# STM32G414xx register map
File version: 1.0
Registers are 32-bit, read-write, reset 0x0 unless marked. A register's access mark holds for its fields unless they carry their own. Offsets are from the block's base; [hi:lo] are bit positions; {n}, {i} and the like mark numbered series; 'fields as' and 'values as' point back to an identical list.

## HRTIM1
Base 0x40016800
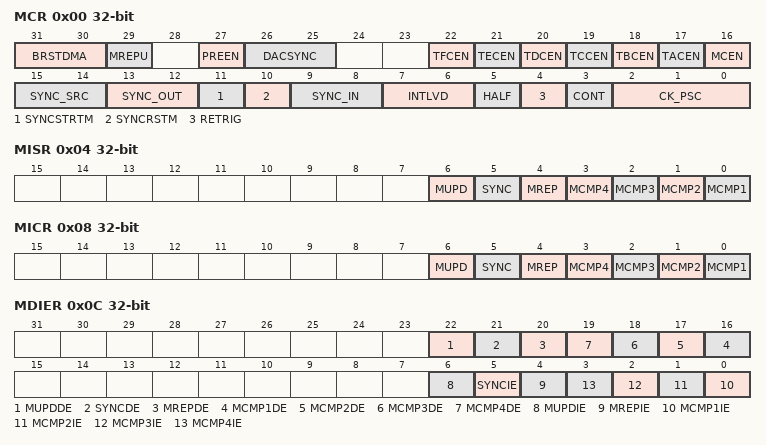
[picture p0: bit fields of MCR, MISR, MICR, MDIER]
0x00 MCR — HRTIM Master Timer control register
  [31:30] BRSTDMA — Burst DMA update
  [29] MREPU — Master repetition update
  [27] PREEN — Master preload enable
  [26:25] DACSYNC — DAC synchronization mask
  [22] TFCEN — Timer F counter enable
  [21] TECEN — Timer E counter enable
  [20] TDCEN — Timer D counter enable
  [19] TCCEN — Timer C counter enable
  [18] TBCEN — Timer B counter enable
  [17] TACEN — Timer A counter enable
  [16] MCEN — Master counter enable
  [15:14] SYNC_SRC — Synchronization source
  [13:12] SYNC_OUT — Synchronization output master
  [11] SYNCSTRTM — Synchronization start master
  [10] SYNCRSTM — Synchronization reset master
  [9:8] SYNC_IN — Synchronization input master
  [7:6] INTLVD — Interleaved mode
  [5] HALF — Half mode
  [4] RETRIG — Rettrigreable mode
  [3] CONT — Continuous mode
  [2:0] CK_PSC — Prescaler mask
0x04 MISR — HRTIM Master Timer interrupt status register
  [6] MUPD — Master update interrupt flag
  [5] SYNC — Synchronization input interrupt flag
  [4] MREP — Master Repetition interrupt flag
  [n-1] MCMP{n} (n=1..4) — Master compare {n} interrupt flag
0x08 MICR — HRTIM Master Timer interrupt clear register
  [6] MUPD — Master update interrupt flag clear
  [5] SYNC — Synchronization input interrupt flag clear
  [4] MREP — Master Repetition interrupt flag clear
  [n-1] MCMP{n} (n=1..4) — Master compare {n} interrupt flag clear
0x0C MDIER — HRTIM Master Timer DMA/interrupt enable register
  [22] MUPDDE — Master update DMA enable
  [21] SYNCDE — Synchronization input DMA enable
  [20] MREPDE — Master Repetition DMA enable
  [n+15] MCMP{n}DE (n=1..4) — Master compare {n} DMA enable
  [6] MUPDIE — Master update interrupt enable
  [5] SYNCIE — Synchronization input interrupt enable
  [4] MREPIE — Master Repetition interrupt enable
  [n-1] MCMP{n}IE (n=1..4) — Master compare {n} interrupt enable
0x10 MCNTR — HRTIM Master Timer counter register
  [15:0] MCNTR — Counter Value
0x14 MPER — HRTIM Master Timer period register
  [15:0] MPER — Period Value
0x18 MREP — HRTIM Master Timer repetition register
  [7:0] MREP — Repetition Value
0x1C MCMP1R — HRTIM Master Timer compare 1 register
  [15:0] MCMP1R — Compare Value
{0x1C+4i} MCMP{i}R (i=2..4) — HRTIM Master Timer compare {i} register
  [15:0] MCMP{i}R — Compare Value
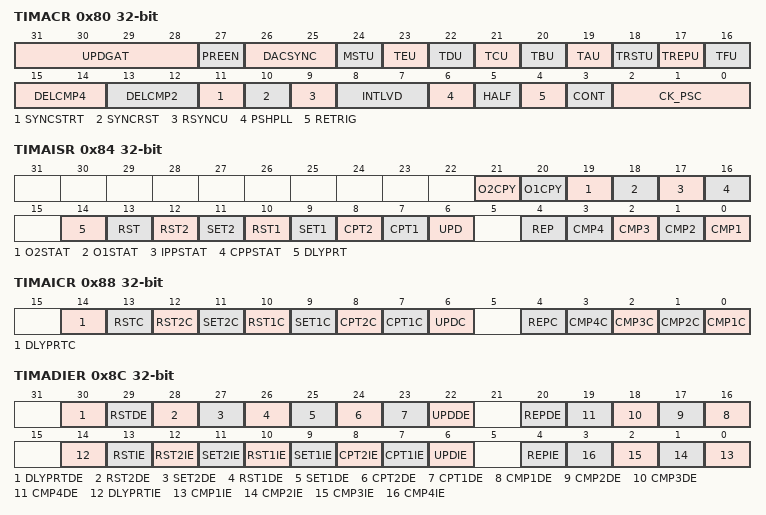
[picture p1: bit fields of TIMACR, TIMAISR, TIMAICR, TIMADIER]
0x80 TIMACR — HRTIM Timerx control register
  [31:28] UPDGAT — Slave update gating mask
  [27] PREEN — Slave preload enable
  [26:25] DACSYNC — DAC synchronization mask
  [24] MSTU — Master Update
  [23] TEU — Slave Timer E update reserved for TIM E
  [22] TDU — Slave Timer D update reserved for TIM D
  [21] TCU — Slave Timer C update reserved for TIM C
  [20] TBU — Slave Timer B update reserved for TIM B
  [19] TAU — Slave Timer A update reserved for TIM A
  [18] TRSTU — Slave reset update
  [17] TREPU — Slave repetition update
  [16] TFU — Slave Timer F update reserved for TIM F
  [15:14] DELCMP4 — Slave delayed compartor 4 mode mask
  [13:12] DELCMP2 — Slave delayed compartor 2 mode mask
  [11] SYNCSTRT — Slave synchronization starts
  [10] SYNCRST — Slave synchronization resets
  [9] RSYNCU — Resynchronization update
  [8:7] INTLVD — Interleaved mode
  [6] PSHPLL — Slave push-pull mode
  [5] HALF — Slave Half mode
  [4] RETRIG — Slave Retrigreable mode
  [3] CONT — Slave continuous mode
  [2:0] CK_PSC — Slave prescaler mask
0x84 TIMAISR — HRTIM Timerx interrupt status register
  [21] O2CPY — Slave output 2 copy flag
  [20] O1CPY — Slave output 1 copy flag
  [19] O2STAT — Slave output 2 state flag
  [18] O1STAT — Slave output 1 state flag
  [17] IPPSTAT — Slave idle push-pull flag
  [16] CPPSTAT — Slave current push-pull flag
  [14] DLYPRT — Slave output 1 delay protection interrupt flag
  [13] RST — Slave reset interrupt flag
  [12] RST2 — Slave output 2 reset interrupt flag
  [11] SET2 — Slave output 2 set interrupt flag
  [10] RST1 — Slave output 1 reset interrupt flag
  [9] SET1 — Slave output 1 set interrupt flag
  [8] CPT2 — Slave capture 2 interrupt flag
  [7] CPT1 — Slave capture 1 interrupt flag
  [6] UPD — Slave update interrupt flag
  [4] REP — Slave repetition interrupt flag
  [n-1] CMP{n} (n=1..4) — Slave compare {n} interrupt flag
0x88 TIMAICR — HRTIM Timerx interrupt clear register
  [14] DLYPRTC — Slave output delay protection clear flag
  [13] RSTC — Slave reset clear flag
  [12] RST2C — Slave output 2 reset clear flag
  [11] SET2C — Slave output 2 set clear flag
  [10] RST1C — Slave output 1 reset clear flag
  [9] SET1C — Slave output 1 set clear flag
  [8] CPT2C — Slave capture 2 clear flag
  [7] CPT1C — Slave capture 1 clear flag
  [6] UPDC — Slave update clear flag
  [4] REPC — Slave repetition clear flag
  [n-1] CMP{n}C (n=1..4) — Slave compare {n} clear flag
0x8C TIMADIER — HRTIM Timerx DMA/interrupt enable register
  [30] DLYPRTDE — Slavedelay protection request enable
  [29] RSTDE — Slave reset request enable
  [28] RST2DE — Slave output 2 reset request enable
  [27] SET2DE — Slave output 2 set request enable
  [26] RST1DE — Slave output 1 reset request enable
  [25] SET1DE — Slave output 1 set request enable
  [24] CPT2DE — Slave capture 2 request enable
  [23] CPT1DE — Slave capture 1 request enable
  [22] UPDDE — Slave update request enable
  [20] REPDE — Slave repetition request enable
  [n+15] CMP{n}DE (n=1..4) — Slave compare {n} request enable
  [14] DLYPRTIE — Slave delay protection interrupt enable
  [13] RSTIE — Slave reset interrupt enable
  [12] RST2IE — Slave output 2 reset interrupt enable
  [11] SET2IE — Slave output 2 set interrupt enable
  [10] RST1IE — Slave output 1 reset interrupt enable
  [9] SET1IE — Slave output 1 set interrupt enable
  [8] CPT2IE — Slave capture 2 interrupt enable
  [7] CPT1IE — Slave capture 1 interrupt enable
  [6] UPDIE — Slave update interrupt enable
  [4] REPIE — Slave repetition interrupt enable
  [n-1] CMP{n}IE (n=1..4) — Slave compare {n} interrupt enable
0x90 CNTAR — HRTIM Timerx counter register
  [15:0] CNTR — Counter Value
0x94 PERAR — HRTIM Timerx period register
0x98 REPAR — HRTIM Timerx repetition register
0x9C CMP1AR — HRTIM Timerx compare 1 register
  [15:0] CMP1R — Compare Value
0xA0 CMP1CAR — HRTIM Timerx compare 1 compound register
  [15:0] CMP1CR — Compare Value
{0x9C+4i} CMP{i}AR (i=2..4) — HRTIM Timerx compare {i} register
  [15:0] CMP{i}R — Compare Value
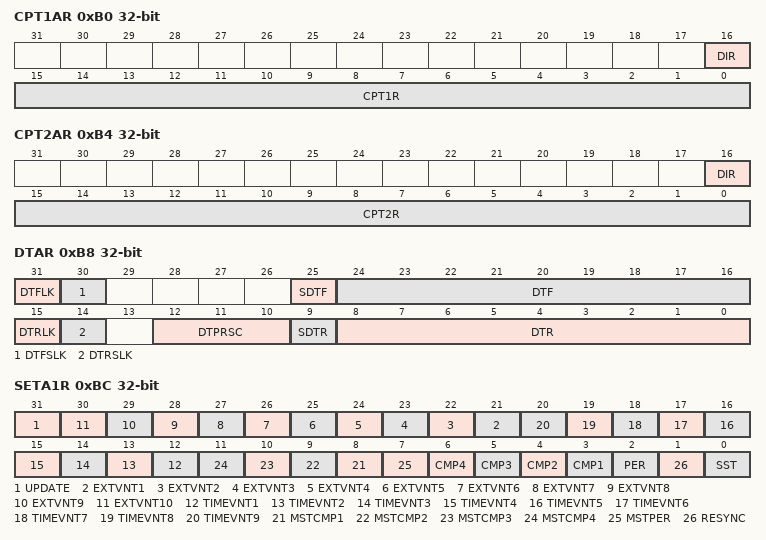
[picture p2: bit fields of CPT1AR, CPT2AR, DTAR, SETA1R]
0xB0 CPT1AR — HRTIM Timerx capture 1 register
  [16] DIR — Capture 1 direction>
  [15:0] CPT1R — Capture 1 Value
0xB4 CPT2AR — HRTIM Timerx capture 2 register
  [16] DIR — Capture 2 direction
  [15:0] CPT2R — Capture 2 Value
0xB8 DTAR — HRTIM Timerx dead time register
  [31] DTFLK — Dead time falling lock
  [30] DTFSLK — Dead time falling sign lock
  [25] SDTF — Sign dead time falling value
  [24:16] DTF — Dead time falling value
  [15] DTRLK — Dead time rising lock
  [14] DTRSLK — Dead time rising sign lock
  [12:10] DTPRSC — Dead time prescaler
  [9] SDTR — Sign dead time rising value
  [8:0] DTR — Dead time rising value
0xBC SETA1R — HRTIM Timerx output 1 set register
  [31] UPDATE — Register update (transfer preload to active)
  [n+20] EXTVNT{n} (n=1..10) — External event {n}
  [n+11] TIMEVNT{n} (n=1..9) — Timer event {n}
  [n+7] MSTCMP{n} (n=1..4) — Master compare {n}
  [7] MSTPER — Master period
  [n+2] CMP{n} (n=1..4) — Timer A compare {n}
  [2] PER — Timer A period
  [1] RESYNC — Timer A resynchronization
  [0] SST — software set trigger
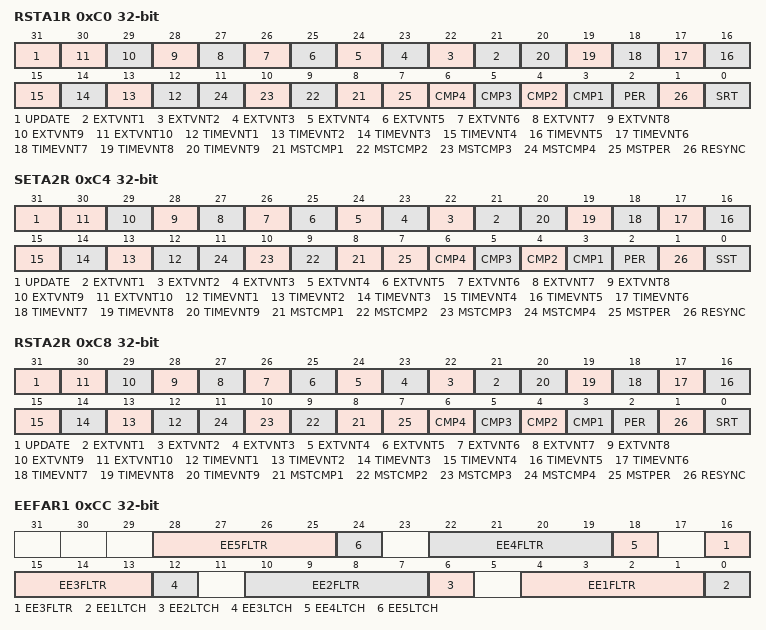
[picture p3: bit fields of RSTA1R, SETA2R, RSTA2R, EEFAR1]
0xC0 RSTA1R — HRTIM Timerx output 1 reset register
  [31] UPDATE — Register update (transfer preload to active)
  [n+20] EXTVNT{n} (n=1..10) — External event {n}
  [n+11] TIMEVNT{n} (n=1..9) — Timer event {n}
  [n+7] MSTCMP{n} (n=1..4) — Master compare {n}
  [7] MSTPER — Master period
  [n+2] CMP{n} (n=1..4) — Timer A compare {n}
  [2] PER — Timer A period
  [1] RESYNC — Timer A resynchronization
  [0] SRT — software reset trigger
0xC4 SETA2R — HRTIM Timerx output 2 set register
  fields as SETA1R
0xC8 RSTA2R — HRTIM Timerx output 2 reset register
  fields as RSTA1R
0xCC EEFAR1 — HRTIM Timerx external event filtering 1 register
  [6n-2:6n-5] EE{n}FLTR (n=1..5) — External Event {n} filter mask
  [6n-6] EE{n}LTCH (n=1..5) — External Event {n} latch
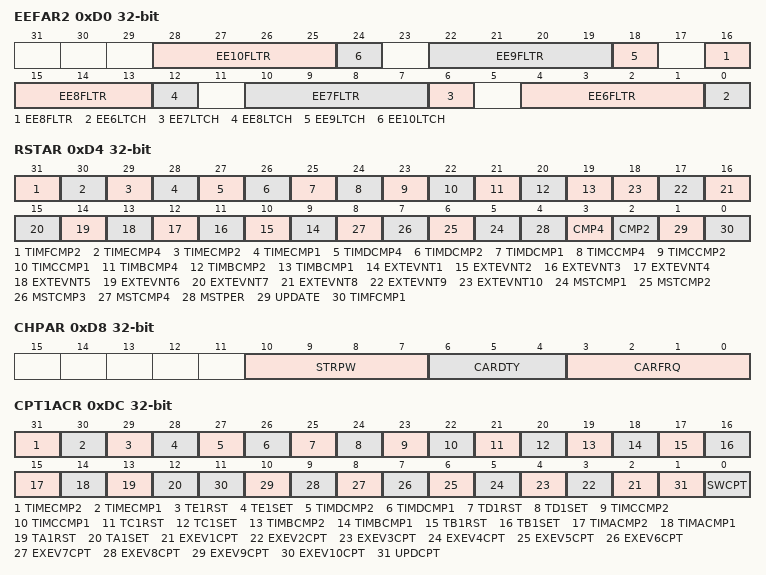
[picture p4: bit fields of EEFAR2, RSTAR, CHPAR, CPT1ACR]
0xD0 EEFAR2 — HRTIM Timerx external event filtering 2 register
  [6n-32:6n-35] EE{n}FLTR (n=6..10) — External Event {n} filter mask
  [6n-36] EE{n}LTCH (n=6..10) — External Event {n} latch
0xD4 RSTAR — HRTIM Timerx Reset register
  [31] TIMFCMP2 — Timer F compare 2
  [30] TIMECMP4 — Timer E compare 4
  [29] TIMECMP2 — Timer E compare 2
  [28] TIMECMP1 — Timer E compare 1
  [27] TIMDCMP4 — Timer D compare 4
  [26] TIMDCMP2 — Timer D compare 2
  [25] TIMDCMP1 — Timer D compare 1
  [24] TIMCCMP4 — Timer C compare 4
  [23] TIMCCMP2 — Timer C compare 2
  [22] TIMCCMP1 — Timer C compare 1
  [21] TIMBCMP4 — Timer B compare 4
  [20] TIMBCMP2 — Timer B compare 2
  [19] TIMBCMP1 — Timer B compare 1
  [n+8] EXTEVNT{n} (n=1..10) — External event {n}
  [n+4] MSTCMP{n} (n=1..4) — Master compare{n}
  [4] MSTPER — Master period
  [3] CMP4 — Timer compare4
  [2] CMP2 — Timer compare2
  [1] UPDATE — Timer update
  [0] TIMFCMP1 — Timer F compare 1
0xD8 CHPAR — HRTIM Timerx Chopper register
  [10:7] STRPW — Timer start pulse width value
  [6:4] CARDTY — Timer chopper duty cycle value
  [3:0] CARFRQ — Timer carrier frequency value
0xDC CPT1ACR — HRTIM Timerx Capture 1 register
  [31] TIMECMP2 — Timer E compare 2
  [30] TIMECMP1 — Timer E compare 1
  [29] TE1RST — Timer E output 1 reset
  [28] TE1SET — Timer E output 1 set
  [27] TIMDCMP2 — Timer D compare 2
  [26] TIMDCMP1 — Timer D compare 1
  [25] TD1RST — Timer D output 1 reset
  [24] TD1SET — Timer D output 1 set
  [23] TIMCCMP2 — Timer C compare 2
  [22] TIMCCMP1 — Timer C compare 1
  [21] TC1RST — Timer C output 1 reset
  [20] TC1SET — Timer C output 1 set
  [19] TIMBCMP2 — Timer B compare 2
  [18] TIMBCMP1 — Timer B compare 1
  [17] TB1RST — Timer B output 1 reset
  [16] TB1SET — Timer B output 1 set
  [15] TIMACMP2 — Timer A compare 2
  [14] TIMACMP1 — Timer A compare 1
  [13] TA1RST — Timer A output 1 reset
  [12] TA1SET — Timer A output 1 set
  [n+1] EXEV{n}CPT (n=1..10) — External event {n} capture
  [1] UPDCPT — Update capture
  [0] SWCPT — Software capture
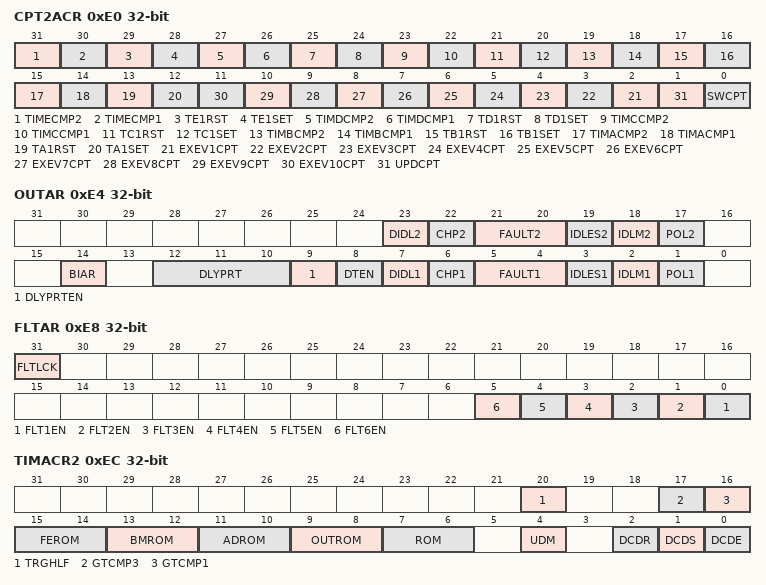
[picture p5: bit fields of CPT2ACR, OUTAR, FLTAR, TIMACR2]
0xE0 CPT2ACR — HRTIM Timerx Capture 2 register
  fields as CPT1ACR
0xE4 OUTAR — HRTIM Timerx Output register
  [23] DIDL2 — Slave output 2 dead time idle
  [22] CHP2 — Slave output 2 chopper enable
  [21:20] FAULT2 — Slave output 2 fault state
  [19] IDLES2 — Slave output 2 idle state
  [18] IDLM2 — Slave output 2 idle mode
  [17] POL2 — Slave output 2 polarity
  [14] BIAR — Slave output Balanced Idle Automatic resume
  [12:10] DLYPRT — Slave output delay protection
  [9] DLYPRTEN — Slave output delay protection enable
  [8] DTEN — Slave output deadtime enable
  [7] DIDL1 — Slave output 1 dead time idle
  [6] CHP1 — Slave output 1 chopper enable
  [5:4] FAULT1 — Slave output 1 fault state
  [3] IDLES1 — Slave output 1 idle state
  [2] IDLM1 — Slave output 1 idle mode
  [1] POL1 — Slave output 1 polarity
0xE8 FLTAR — HRTIM Timerx Fault register
  [31] FLTLCK — Fault sources lock
  [n-1] FLT{n}EN (n=1..6) — Fault {n} enable
0xEC TIMACR2 — HRTIM Timerx Control register 2
  [20] TRGHLF — Triggered-Half mode
  [17] GTCMP3 — Greater than Compare 3 PWM mode
  [16] GTCMP1 — Greater than Compare 1 PWM mode
  [15:14] FEROM — Fault and Event Rollover Mode
  [13:12] BMROM — Burst Mode Rollover Mode
  [11:10] ADROM — ADC Roll-Over Mode
  [9:8] OUTROM — Output Roll-Over Mode
  [7:6] ROM — Roll-over Mode
  [4] UDM — Up-Down Mode
  [2] DCDR — Dual Channel DAC reset trigger
  [1] DCDS — Dual Channel DAC step trigger
  [0] DCDE — Dual Channel DAC trigger enable
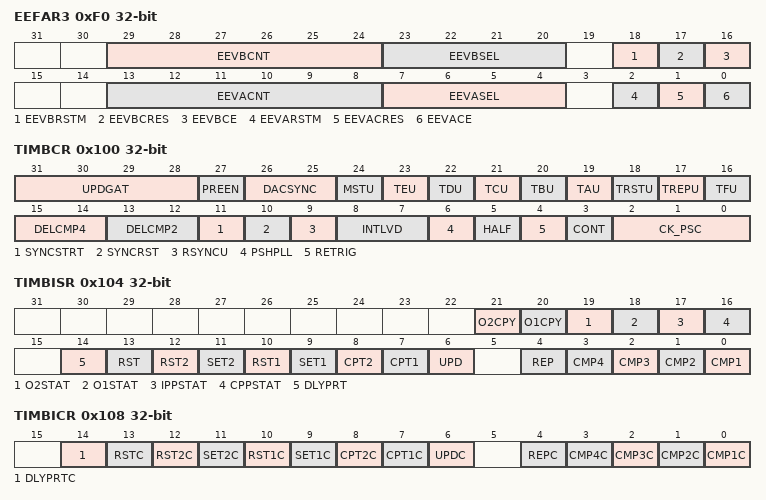
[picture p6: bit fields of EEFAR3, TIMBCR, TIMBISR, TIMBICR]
0xF0 EEFAR3 — HRTIM Timerx external event filtering 3 register
  [29:24] EEVBCNT — External Event B Counter
  [23:20] EEVBSEL — External Event B Selection
  [18] EEVBRSTM — External Event B Counter Reset Mode
  [17] EEVBCRES — External Event B Counter Reset
  [16] EEVBCE — External Event B Counter Enable
  [13:8] EEVACNT — External Event A Selection
  [7:4] EEVASEL — External Event A Selection
  [2] EEVARSTM — External Event A Counter Reset Mode
  [1] EEVACRES — External Event A Counter Reset
  [0] EEVACE — External Event A Counter Enable
0x100 TIMBCR — HRTIM Timerx control register
  fields as TIMACR
0x104 TIMBISR — HRTIM Timerx interrupt status register
  fields as TIMAISR
0x108 TIMBICR — HRTIM Timerx interrupt clear register
  fields as TIMAICR
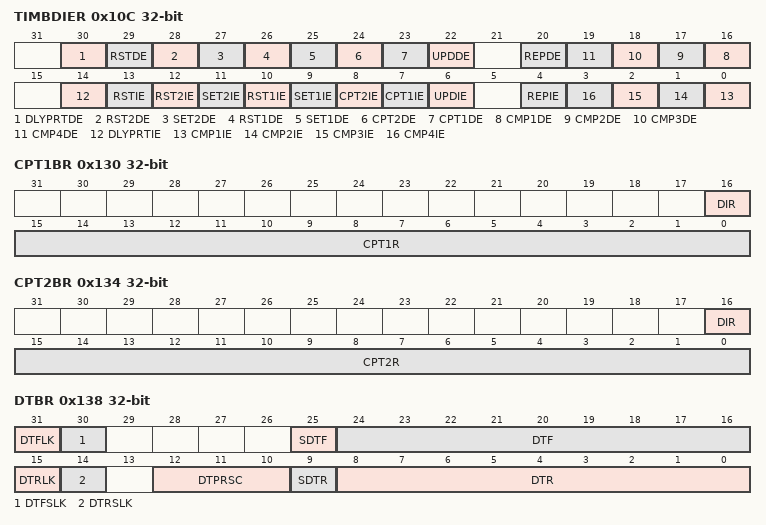
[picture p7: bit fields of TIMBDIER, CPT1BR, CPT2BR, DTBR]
0x10C TIMBDIER — HRTIM Timerx DMA/interrupt enable register
  fields as TIMADIER
0x110 CNTBR — HRTIM Timerx counter register
  [15:0] CNTR — Counter Value
0x114 PERBR — HRTIM Timerx period register
0x118 REPBR — HRTIM Timerx repetition register
0x11C CMP1BR — HRTIM Timerx compare 1 register
  [15:0] CMP1R — Compare Value
0x120 CMP1CBR — HRTIM Timerx compare 1 compound register
  [15:0] CMP1CR — Compare Value
{0x11C+4i} CMP{i}BR (i=2..4) — HRTIM Timerx compare {i} register
  [15:0] CMP{i}R — Compare Value
0x130 CPT1BR — HRTIM Timerx capture 1 register
  [16] DIR — Capture 1 direction>
  [15:0] CPT1R — Capture 1 Value
0x134 CPT2BR — HRTIM Timerx capture 2 register
  [16] DIR — Capture 2 direction
  [15:0] CPT2R — Capture 2 Value
0x138 DTBR — HRTIM Timerx dead time register
  fields as DTAR
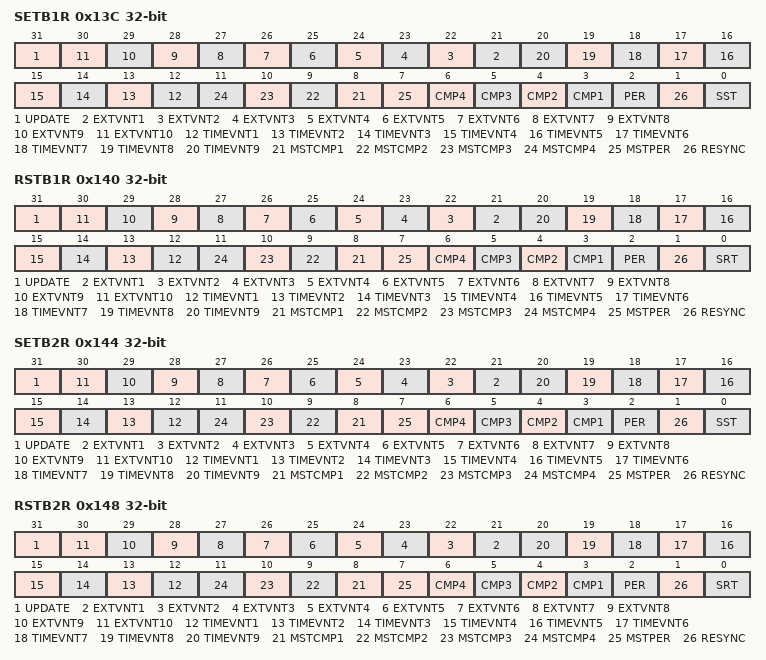
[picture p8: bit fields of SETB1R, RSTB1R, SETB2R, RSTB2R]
0x13C SETB1R — HRTIM Timerx output 1 set register
  fields as SETA1R
0x140 RSTB1R — HRTIM Timerx output 1 reset register
  fields as RSTA1R
0x144 SETB2R — HRTIM Timerx output 2 set register
  fields as SETA1R
0x148 RSTB2R — HRTIM Timerx output 2 reset register
  fields as RSTA1R
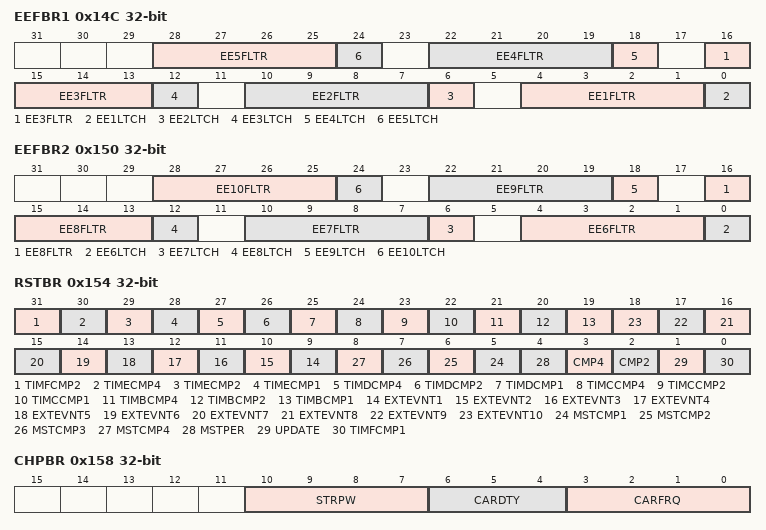
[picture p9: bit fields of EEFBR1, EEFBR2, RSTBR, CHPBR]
0x14C EEFBR1 — HRTIM Timerx external event filtering 1 register
  fields as EEFAR1
0x150 EEFBR2 — HRTIM Timerx external event filtering 2 register
  fields as EEFAR2
0x154 RSTBR — HRTIM Timerx Reset register
  fields as RSTAR
0x158 CHPBR — HRTIM Timerx Chopper register
  fields as CHPAR
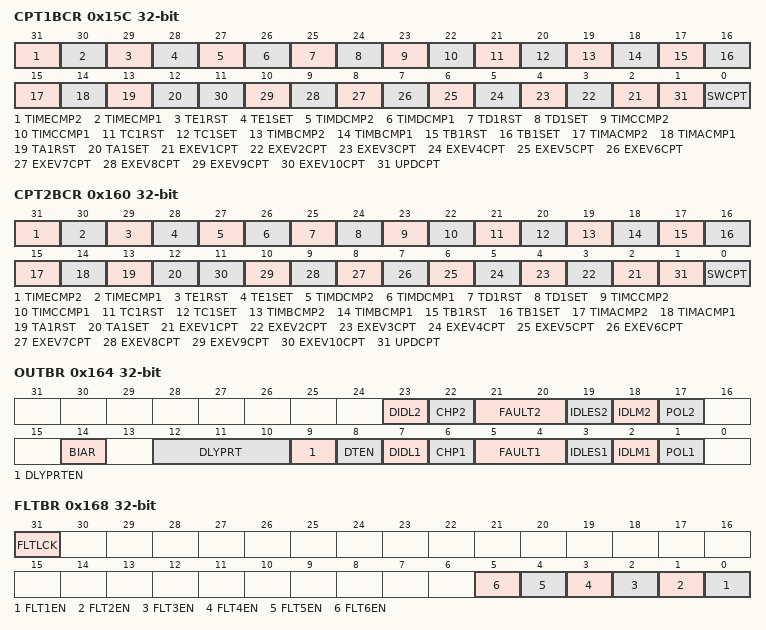
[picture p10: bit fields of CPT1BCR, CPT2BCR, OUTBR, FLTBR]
0x15C CPT1BCR — HRTIM Timerx Capture 1 register
  fields as CPT1ACR
0x160 CPT2BCR — HRTIM Timerx Capture 2 register
  fields as CPT1ACR
0x164 OUTBR — HRTIM Timerx Output register
  fields as OUTAR
0x168 FLTBR — HRTIM Timerx Fault register
  fields as FLTAR
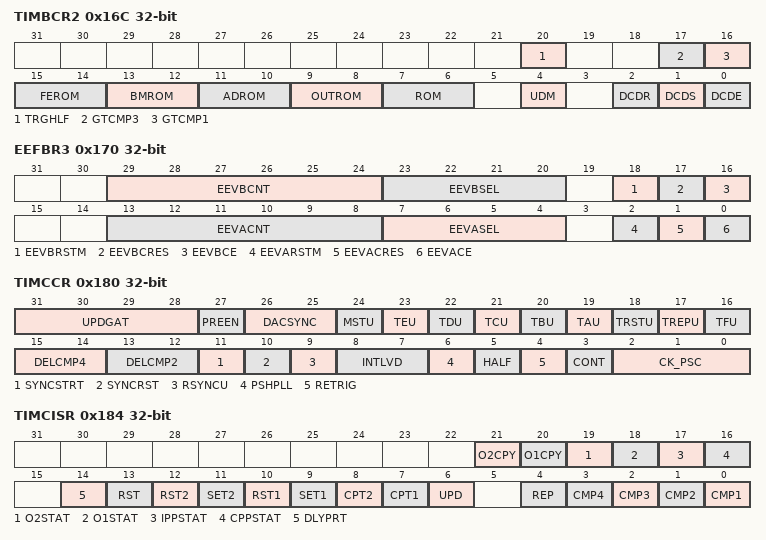
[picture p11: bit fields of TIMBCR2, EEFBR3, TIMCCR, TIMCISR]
0x16C TIMBCR2 — HRTIM Timerx Control register 2
  fields as TIMACR2
0x170 EEFBR3 — HRTIM Timerx external event filtering 3 register
  fields as EEFAR3
0x180 TIMCCR — HRTIM Timerx control register
  fields as TIMACR
0x184 TIMCISR — HRTIM Timerx interrupt status register
  fields as TIMAISR
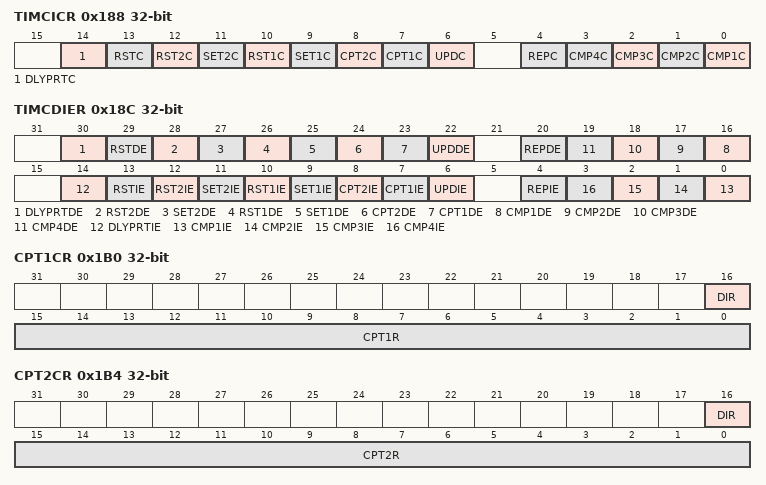
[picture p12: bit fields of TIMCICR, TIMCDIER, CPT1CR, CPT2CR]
0x188 TIMCICR — HRTIM Timerx interrupt clear register
  fields as TIMAICR
0x18C TIMCDIER — HRTIM Timerx DMA/interrupt enable register
  fields as TIMADIER
0x190 CNTCR — HRTIM Timerx counter register
  [15:0] CNTR — Counter Value
0x194 PERCR — HRTIM Timerx period register
0x198 REPCR — HRTIM Timerx repetition register
0x19C CMP1CR — HRTIM Timerx compare 1 register
  [15:0] CMP1R — Compare Value
0x1A0 CMP1CCR — HRTIM Timerx compare 1 compound register
  [15:0] CMP1CR — Compare Value
{0x19C+4i} CMP{i}CR (i=2..4) — HRTIM Timerx compare {i} register
  [15:0] CMP{i}R — Compare Value
0x1B0 CPT1CR — HRTIM Timerx capture 1 register
  [16] DIR — Capture 1 direction>
  [15:0] CPT1R — Capture 1 Value
0x1B4 CPT2CR — HRTIM Timerx capture 2 register
  [16] DIR — Capture 2 direction
  [15:0] CPT2R — Capture 2 Value
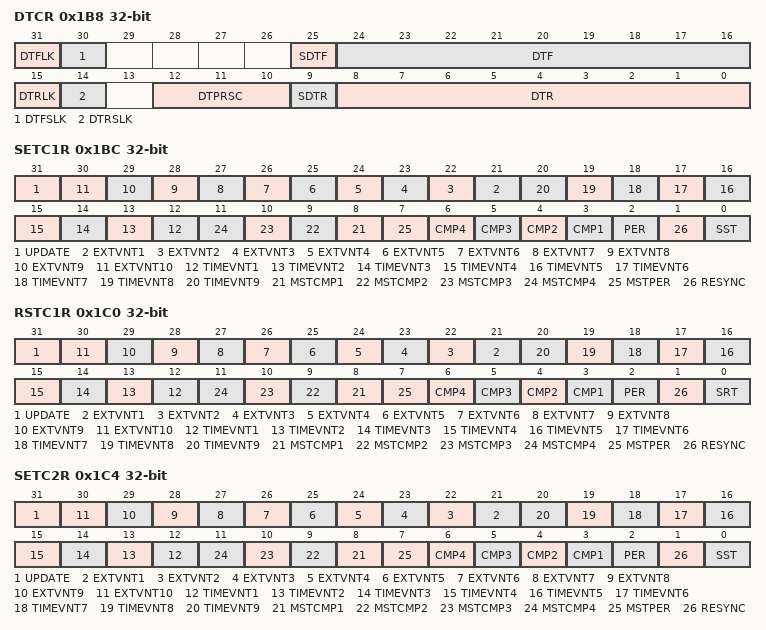
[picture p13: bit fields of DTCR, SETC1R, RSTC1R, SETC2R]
0x1B8 DTCR — HRTIM Timerx dead time register
  fields as DTAR
0x1BC SETC1R — HRTIM Timerx output 1 set register
  fields as SETA1R
0x1C0 RSTC1R — HRTIM Timerx output 1 reset register
  fields as RSTA1R
0x1C4 SETC2R — HRTIM Timerx output 2 set register
  fields as SETA1R
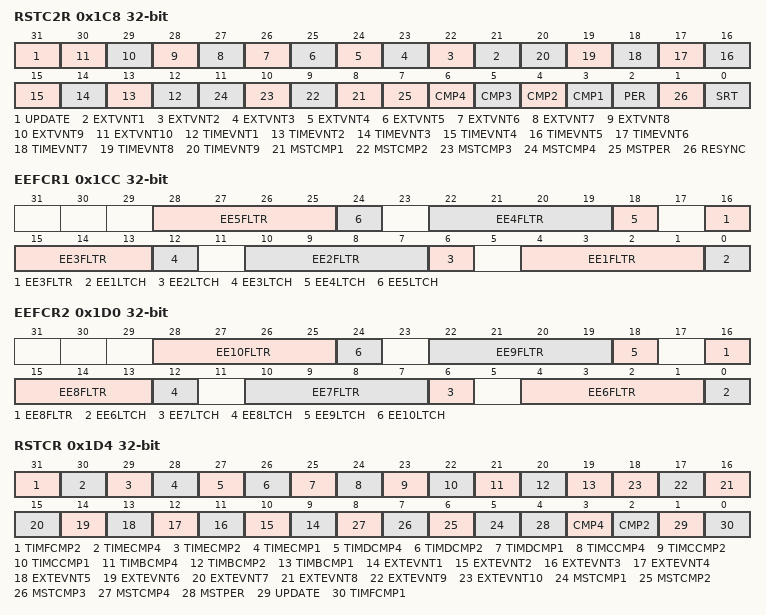
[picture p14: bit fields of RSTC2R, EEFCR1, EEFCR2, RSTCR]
0x1C8 RSTC2R — HRTIM Timerx output 2 reset register
  fields as RSTA1R
0x1CC EEFCR1 — HRTIM Timerx external event filtering 1 register
  fields as EEFAR1
0x1D0 EEFCR2 — HRTIM Timerx external event filtering 2 register
  fields as EEFAR2
0x1D4 RSTCR — HRTIM Timerx Reset register
  fields as RSTAR
0x1D8 CHPCR — HRTIM Timerx Chopper register
  fields as CHPAR
0x1DC CPT1CCR — HRTIM Timerx Capture 1 register
  fields as CPT1ACR
0x1E0 CPT2CCR — HRTIM Timerx Capture 2 register
  fields as CPT1ACR
0x1E4 OUTCR — HRTIM Timerx Output register
  fields as OUTAR
0x1E8 FLTCR — HRTIM Timerx Fault register
  fields as FLTAR
0x1EC TIMCCR2 — HRTIM Timerx Control register 2
  fields as TIMACR2
0x1F0 EEFCR3 — HRTIM Timerx external event filtering 3 register
  fields as EEFAR3
0x200 TIMDCR — HRTIM Timerx control register
  fields as TIMACR
0x204 TIMDISR — HRTIM Timerx interrupt status register
  fields as TIMAISR
0x208 TIMDICR — HRTIM Timerx interrupt clear register
  fields as TIMAICR
0x20C TIMDDIER — HRTIM Timerx DMA/interrupt enable register
  fields as TIMADIER
0x210 CNTDR — HRTIM Timerx counter register
  [15:0] CNTR — Counter Value
0x214 PERDR — HRTIM Timerx period register
0x218 REPDR — HRTIM Timerx repetition register
0x21C CMP1DR — HRTIM Timerx compare 1 register
  [15:0] CMP1R — Compare Value
0x220 CMP1CDR — HRTIM Timerx compare 1 compound register
  [15:0] CMP1CR — Compare Value
{0x21C+4i} CMP{i}DR (i=2..4) — HRTIM Timerx compare {i} register
  [15:0] CMP{i}R — Compare Value
0x230 CPT1DR — HRTIM Timerx capture 1 register
  [16] DIR — Capture 1 direction>
  [15:0] CPT1R — Capture 1 Value
0x234 CPT2DR — HRTIM Timerx capture 2 register
  [16] DIR — Capture 2 direction
  [15:0] CPT2R — Capture 2 Value
0x238 DTDR — HRTIM Timerx dead time register
  fields as DTAR
0x23C SETD1R — HRTIM Timerx output 1 set register
  fields as SETA1R
0x240 RSTD1R — HRTIM Timerx output 1 reset register
  fields as RSTA1R
0x244 SETD2R — HRTIM Timerx output 2 set register
  fields as SETA1R
0x248 RSTD2R — HRTIM Timerx output 2 reset register
  fields as RSTA1R
0x24C EEFDR1 — HRTIM Timerx external event filtering 1 register
  fields as EEFAR1
0x250 EEFDR2 — HRTIM Timerx external event filtering 2 register
  fields as EEFAR2
0x254 RSTDR — HRTIM Timerx Reset register
  fields as RSTAR
0x258 CHPDR — HRTIM Timerx Chopper register
  fields as CHPAR
0x25C CPT1DCR — HRTIM Timerx Capture 1 register
  fields as CPT1ACR
0x260 CPT2DCR — HRTIM Timerx Capture 2 register
  fields as CPT1ACR
0x264 OUTDR — HRTIM Timerx Output register
  fields as OUTAR
0x268 FLTDR — HRTIM Timerx Fault register
  fields as FLTAR
0x26C TIMDCR2 — HRTIM Timerx Control register 2
  fields as TIMACR2
0x270 EEFDR3 — HRTIM Timerx external event filtering 3 register
  fields as EEFAR3
0x280 TIMECR — HRTIM Timerx control register
  fields as TIMACR
0x284 TIMEISR — HRTIM Timerx interrupt status register
  fields as TIMAISR
0x288 TIMEICR — HRTIM Timerx interrupt clear register
  fields as TIMAICR
0x28C TIMEDIER — HRTIM Timerx DMA/interrupt enable register
  fields as TIMADIER
0x290 CNTER — HRTIM Timerx counter register
  [15:0] CNTR — Counter Value
0x294 PERER — HRTIM Timerx period register
0x298 REPER — HRTIM Timerx repetition register
0x29C CMP1ER — HRTIM Timerx compare 1 register
  [15:0] CMP1R — Compare Value
0x2A0 CMP1CER — HRTIM Timerx compare 1 compound register
  [15:0] CMP1CR — Compare Value
{0x29C+4i} CMP{i}ER (i=2..4) — HRTIM Timerx compare {i} register
  [15:0] CMP{i}R — Compare Value
0x2B0 CPT1ER — HRTIM Timerx capture 1 register
  [16] DIR — Capture 1 direction>
  [15:0] CPT1R — Capture 1 Value
0x2B4 CPT2ER — HRTIM Timerx capture 2 register
  [16] DIR — Capture 2 direction
  [15:0] CPT2R — Capture 2 Value
0x2B8 DTER — HRTIM Timerx dead time register
  fields as DTAR
0x2BC SETE1R — HRTIM Timerx output 1 set register
  fields as SETA1R
0x2C0 RSTE1R — HRTIM Timerx output 1 reset register
  fields as RSTA1R
0x2C4 SETE2R — HRTIM Timerx output 2 set register
  fields as SETA1R
0x2C8 RSTE2R — HRTIM Timerx output 2 reset register
  fields as RSTA1R
0x2CC EEFER1 — HRTIM Timerx external event filtering 1 register
  fields as EEFAR1
0x2D0 EEFER2 — HRTIM Timerx external event filtering 2 register
  fields as EEFAR2
0x2D4 RSTER — HRTIM Timerx Reset register
  fields as RSTAR
0x2D8 CHPER — HRTIM Timerx Chopper register
  fields as CHPAR
0x2DC CPT1ECR — HRTIM Timerx Capture 1 register
  fields as CPT1ACR
0x2E0 CPT2ECR — HRTIM Timerx Capture 2 register
  fields as CPT1ACR
0x2E4 OUTER — HRTIM Timerx Output register
  fields as OUTAR
0x2E8 FLTER — HRTIM Timerx Fault register
  fields as FLTAR
0x2EC TIMECR2 — HRTIM Timerx Control register 2
  fields as TIMACR2
0x2F0 EEFER3 — HRTIM Timerx external event filtering 3 register
  fields as EEFAR3
0x300 TIMFCR — HRTIM Timerx control register
  fields as TIMACR
0x304 TIMFISR — HRTIM Timerx interrupt status register
  fields as TIMAISR
0x308 TIMFICR — HRTIM Timerx interrupt clear register
  fields as TIMAICR
0x30C TIMFDIER — HRTIM Timerx DMA/interrupt enable register
  fields as TIMADIER
0x310 CNTFR — HRTIM Timerx counter register
  [15:0] CNTR — Counter Value
0x314 PERFR — HRTIM Timerx period register
0x318 REPFR — HRTIM Timerx repetition register
0x31C CMP1FR — HRTIM Timerx compare 1 register
  [15:0] CMP1R — Compare Value
0x320 CMP1CFR — HRTIM Timerx compare 1 compound register
  [15:0] CMP1CR — Compare Value
{0x31C+4i} CMP{i}FR (i=2..4) — HRTIM Timerx compare {i} register
  [15:0] CMP{i}R — Compare Value
0x330 CPT1FR — HRTIM Timerx capture 1 register
  [16] DIR — Capture 1 direction>
  [15:0] CPT1R — Capture 1 Value
0x334 CPT2FR — HRTIM Timerx capture 2 register
  [16] DIR — Capture 2 direction
  [15:0] CPT2R — Capture 2 Value
0x338 DTFR — HRTIM Timerx dead time register
  fields as DTAR
0x33C SETF1R — HRTIM Timerx output 1 set register
  fields as SETA1R
0x340 RSTF1R — HRTIM Timerx output 1 reset register
  fields as RSTA1R
0x344 SETF2R — HRTIM Timerx output 2 set register
  fields as SETA1R
0x348 RSTF2R — HRTIM Timerx output 2 reset register
  fields as RSTA1R
0x34C EEFFR1 — HRTIM Timerx external event filtering 1 register
  fields as EEFAR1
0x350 EEFFR2 — HRTIM Timerx external event filtering 2 register
  fields as EEFAR2
0x354 RSTFR — HRTIM Timerx Reset register
  fields as RSTAR
0x358 CHPFR — HRTIM Timerx Chopper register
  fields as CHPAR
0x35C CPT1FCR — HRTIM Timerx Capture 1 register
  fields as CPT1ACR
0x360 CPT2FCR — HRTIM Timerx Capture 2 register
  fields as CPT1ACR
0x364 OUTFR — HRTIM Timerx Output register
  fields as OUTAR
0x368 FLTFR — HRTIM Timerx Fault register
  fields as FLTAR
0x36C TIMFCR2 — HRTIM Timerx Control register 2
  fields as TIMACR2
0x370 EEFFR3 — HRTIM Timerx external event filtering 3 register
  fields as EEFAR3
0x380 CR1 — HRTIM control register1
  [3n+15:3n+13] ADC{n}USRC (n=1..4) — ADC Trigger {n} update source
  [6] TFUDIS — Timer F update disable
  [5] TEUDIS — Timer E update disable
  [4] TDUDIS — Timer D update disable
  [3] TCUDIS — Timer C update disable
  [2] TBUDIS — Timer B update disable
  [1] TAUDIS — Timer A update disable
  [0] MUDIS — Master update disable
0x384 CR2 — HRTIM control register2
  [21] SWPF — Timer F swap outputs
  [20] SWPE — Timer E swap outputs
  [19] SWPD — Timer D swap outputs
  [18] SWPC — Timer C swap outputs
  [17] SWPB — Timer B swap outputs
  [16] SWPA — Timer A swap outputs
  [14] TFRST — Timer F count software reset
  [13] TERST — Timer E count software reset
  [12] TDRST — Timer D count software reset
  [11] TCRST — Timer C count software reset
  [10] TBRST — Timer B count software reset
  [9] TARST — Timer A count software reset
  [8] MRST — Master count software reset
  [6] TFSWU — Timer F software update
  [5] TESWU — Timer E software update
  [4] TDSWU — Timer D software update
  [3] TCSWU — Timer C software update
  [2] TBSWU — Timer B software update
  [1] TASWU — Timer A software update
  [0] MSWU — Master software update
0x388 ISR — HRTIM interrupt status register
  [17] BMPER — Burst mode period interrupt flag
  [16] DLLRDY — DLL ready interrupt flag
  [6] FLT6 — Fault 6 interrupt flag
  [5] SYSFLT — System Fault interrupt flag
  [n-1] FLT{n} (n=1..5) — Fault {n} interrupt flag
0x38C ICR — HRTIM interrupt clear register
  [17] BMPERC — Burst mode period interrupt flag clear
  [16] DLLRDYC — DLL ready interrupt flag clear
  [6] FLT6C — Fault 6 interrupt flag clear
  [5] SYSFLTC — System Fault interrupt flag clear
  [n-1] FLT{n}C (n=1..5) — Fault {n} interrupt flag clear
0x390 IER — HRTIM interrupt enable register
  [17] BMPER — Burst mode period interrupt enable
  [16] DLLRDY — DLL ready interrupt enable
  [6] FLT6 — Fault 6 interrupt enable
  [5] SYSFLT — System Fault interrupt enable
  [n-1] FLT{n} (n=1..5) — Fault {n} interrupt enable
0x394 OENR — HRTIM Output enable register
  [11] TF2OEN — Timer F Output 2 enable
  [10] TF1OEN — Timer F Output 1 enable
  [9] TE2OEN — Timer E Output 2 enable
  [8] TE1OEN — Timer E Output 1 enable
  [7] TD2OEN — Timer D Output 2 enable
  [6] TD1OEN — Timer D Output 1 enable
  [5] TC2OEN — Timer C Output 2 enable
  [4] TC1OEN — Timer C Output 1 enable
  [3] TB2OEN — Timer B Output 2 enable
  [2] TB1OEN — Timer B Output 1 enable
  [1] TA2OEN — Timer A Output 2 enable
  [0] TA1OEN — Timer A Output 1 enable
0x398 ODISR — HRTIM Output disable register
  [11] TF2ODIS — Timer F Output 2 disable
  [10] TF1ODIS — Timer F Output 1 disable
  [9] TE2ODIS — Timer E Output 2 disable
  [8] TE1ODIS — Timer E Output 1 disable
  [7] TD2ODIS — Timer D Output 2 disable
  [6] TD1ODIS — Timer D Output 1 disable
  [5] TC2ODIS — Timer C Output 2 disable
  [4] TC1ODIS — Timer C Output 1 disable
  [3] TB2ODIS — Timer B Output 2 disable
  [2] TB1ODIS — Timer B Output 1 disable
  [1] TA2ODIS — Timer A Output 2 disable
  [0] TA1ODIS — Timer A Output 1 disable
0x39C ODSR — HRTIM Output disable status register
  [11] TF2ODS — Timer F Output 2 disable status
  [10] TF1ODS — Timer F Output 1 disable status
  [9] TE2ODS — Timer E Output 2 disable status
  [8] TE1ODS — Timer E Output 1 disable status
  [7] TD2ODS — Timer D Output 2 disable status
  [6] TD1ODS — Timer D Output 1 disable status
  [5] TC2ODS — Timer C Output 2 disable status
  [4] TC1ODS — Timer C Output 1 disable status
  [3] TB2ODS — Timer B Output 2 disable status
  [2] TB1ODS — Timer B Output 1 disable status
  [1] TA2ODS — Timer A Output 2 disable status
  [0] TA1ODS — Timer A Output 1 disable status
0x3A0 BMCR — HRTIM Burst mode control register
  [31] BMSTAT — Burst mode status
  [22] TFBM — Timer F Burst mode
  [21] TEBM — Timer E Burst mode
  [20] TDBM — Timer D Burst mode
  [19] TCBM — Timer C Burst mode
  [18] TBBM — Timer B Burst mode
  [17] TABM — Timer A Burst mode
  [16] MTBM — Master Timer Burst mode
  [10] BMPREN — Burst mode Preload bit
  [9:6] BMPRSC — Burst mode prescaler
  [5:2] BMCLK — Burst mode clock source
  [1] BMOM — Burst mode operating mode
  [0] BME — Burst mode enable
0x3A4 BMTRGR — HRTIM Busrt mode trigger register
  [31] OCHPEV — on-chip Event
  [30] EEV8 — External Event 8
  [29] EEV7 — External Event 7
  [28] TDEEV8 — Timer D period following External Event8
  [27] TAEEV7 — Timer A period following External Event7
  [26] TECMP2 — Timer E compare 2
  [25] TECMP1 — Timer E compare 1
  [24] TEREP — Timer E repetition
  [23] TFCMP1 — Timer F compare 1
  [22] TDCMP2 — Timer D compare 2
  [21] TFREP — Timer F repetition
  [20] TDREP — Timer D repetition
  [19] TDRST — Timer D reset
  [18] TFRST — Timer F reset
  [17] TCCMP1 — Timer C compare 1
  [16] TCREP — Timer C repetition
  [15] TCRST — Timer C reset
  [14] TBCMP2 — Timer B compare 2
  [13] TBCMP1 — Timer B compare 1
  [12] TBREP — Timer B repetition
  [11] TBRST — Timer B reset
  [10] TACMP2 — Timer A compare 2
  [9] TACMP1 — Timer A compare 1
  [8] TAREP — Timer A repetition
  [7] TARST — Timer A reset
  [n+2] MSTCMP{n} (n=1..4) — Master compare {n}
  [2] MSTREP — Master repetition
  [1] MSTRST — Master reset
  [0] SW — Software start
0x3A8 BMCMPR — HRTIM Burst mode compare register
  [15:0] BMCMPR — !<Burst Compare Value
0x3AC BMPER — HRTIM Burst mode period register
  [15:0] BMPER — !<Burst period Value
0x3B0 EECR1 — HRTIM Timer external event control register1
  [6n-1] EE{n}FAST (n=1..5) — External event {n} Fast mode
  [6n-2:6n-3] EE{n}SNS (n=1..5) — External event {n} sensitivity
  [6n-4] EE{n}POL (n=1..5) — External event {n} Polarity
  [6n-5:6n-6] EE{n}SRC (n=1..5) — External event {n} source
0x3B4 EECR2 — HRTIM Timer external event control register2
  [6n-32:6n-33] EE{n}SNS (n=6..10) — External event {n} sensitivity
  [6n-34] EE{n}POL (n=6..10) — External event {n} Polarity
  [6n-35:6n-36] EE{n}SRC (n=6..10) — External event {n} source
0x3B8 EECR3 — HRTIM Timer external event control register3
  [31:30] EEVSD — External event sampling clock division
  [6n-33:6n-36] EE{n}F (n=6..10) — External event {n} filter
0x3BC ADC1R — HRTIM ADC Trigger 1 register
  [31] AD1TEPER — ADC Trigger 1 on Timer E compare period
  [30] AD1TEC4 — ADC Trigger 1 on Timer E compare 4
  [29] AD1TEC3 — ADC Trigger 1 on Timer E compare 3
  [28] AD1TFRST — ADC Trigger 1 on Timer F reset
  [27] AD1TDPER — ADC Trigger 1 on Timer D period
  [26] AD1TDC4 — ADC Trigger 1 on Timer D compare 4
  [25] AD1TDC3 — ADC Trigger 1 on Timer D compare 3
  [24] AD1TFPER — ADC Trigger 1 on Timer F period
  [23] AD1TCPER — ADC Trigger 1 on Timer C period
  [22] AD1TCC4 — ADC Trigger 1 on Timer C compare 4
  [21] AD1TCC3 — ADC Trigger 1 on Timer C compare 3
  [20] AD1TFC4 — ADC Trigger 1 on Timer F compare 4
  [19] AD1TBRST — ADC Trigger 1 on Timer B reset
  [18] AD1TBPER — ADC Trigger 1 on Timer B period
  [17] AD1TBC4 — ADC Trigger 1 on Timer B compare 4
  [16] AD1TBC3 — ADC Trigger 1 on Timer B compare 3
  [15] AD1TFC3 — ADC Trigger 1 on Timer F compare 3
  [14] AD1TARST — ADC Trigger 1 on Timer A reset
  [13] AD1TAPER — ADC Trigger 1 on Timer A period
  [12] AD1TAC4 — ADC Trigger 1 on Timer A compare 4
  [11] AD1TAC3 — ADC Trigger 1 on Timer A compare 3
  [10] AD1TFC2 — ADC Trigger 1 on Timer F compare 2
  [n+4] AD1EEV{n} (n=1..5) — ADC Trigger 1 on external event {n}
  [4] AD1MPER — ADC Trigger 1 on master period
  [n-1] AD1MC{n} (n=1..4) — ADC Trigger 1 on master compare {n}
0x3C0 ADC2R — HRTIM ADC Trigger 2 register
  [31] AD2TERST — ADC Trigger 2 on Timer E reset
  [30] AD2TEC4 — ADC Trigger 2 on Timer E compare 4
  [29] AD2TEC3 — ADC Trigger 2 on Timer E compare 3
  [28] AD2TEC2 — ADC Trigger 2 on Timer E compare 2
  [27] AD2TDRST — ADC Trigger 2 on Timer D reset
  [26] AD2TDPER — ADC Trigger 2 on Timer D period
  [25] AD2TDC4 — ADC Trigger 2 on Timer D compare 4
  [24] AD2TFPER — ADC Trigger 2 on Timer F period
  [23] AD2TDC2 — ADC Trigger 2 on Timer D compare 2
  [22] AD2TCRST — ADC Trigger 2 on Timer C reset
  [21] AD2TCPER — ADC Trigger 2 on Timer C period
  [20] AD2TCC4 — ADC Trigger 2 on Timer C compare 4
  [19] AD2TFC4 — ADC Trigger 2 on Timer F compare 4
  [18] AD2TCC2 — ADC Trigger 2 on Timer C compare 2
  [17] AD2TBPER — ADC Trigger 2 on Timer B period
  [16] AD2TBC4 — ADC Trigger 2 on Timer B compare 4
  [15] AD2TFC3 — ADC Trigger 2 on Timer F compare 3
  [14] AD2TBC2 — ADC Trigger 2 on Timer B compare 2
  [13] AD2TAPER — ADC Trigger 2 on Timer A period
  [12] AD2TAC4 — ADC Trigger 2 on Timer A compare 4
  [11] AD2TFC2 — ADC Trigger 2 on Timer F compare 2
  [10] AD2TAC2 — ADC Trigger 2 on Timer A compare 2
  [n-1] AD2EEV{n} (n=6..10) — ADC Trigger 2 on external event {n}
  [4] AD2MPER — ADC Trigger 2 on master period
  [n-1] AD2MC{n} (n=1..4) — ADC Trigger 2 on master compare {n}
0x3C4 ADC3R — HRTIM ADC Trigger 3 register
  [31] AD3TEPER — ADC Trigger 3 on Timer E period
  [30] AD3TEC4 — ADC Trigger 3 on Timer E compare 4
  [29] AD3TEC3 — ADC Trigger 3 on Timer E compare 3
  [28] AD3TFRST — ADC Trigger 3 on Timer F reset
  [27] AD3TDPER — ADC Trigger 3 on Timer D period
  [26] AD3TDC4 — ADC Trigger 3 on Timer D compare 4
  [25] AD3TDC3 — ADC Trigger 3 on Timer D compare 3
  [24] AD3TFPER — ADC Trigger 3 on Timer F period
  [23] AD3TCPER — ADC Trigger 3 on Timer C period
  [22] AD3TCC4 — ADC Trigger 3 on Timer C compare 4
  [21] AD3TCC3 — ADC Trigger 3 on Timer C compare 3
  [20] AD3TFC4 — ADC Trigger 3 on Timer F compare 4
  [19] AD3TBRST — ADC Trigger 3 on Timer B reset
  [18] AD3TBPER — ADC Trigger 3 on Timer B period
  [17] AD3TBC4 — ADC Trigger 3 on Timer B compare 4
  [16] AD3TBC3 — ADC Trigger 3 on Timer B compare 3
  [15] AD3TFC3 — ADC Trigger 3 on Timer F compare 3
  [14] AD3TARST — ADC Trigger 3 on Timer A reset
  [13] AD3TAPER — ADC Trigger 3 on Timer A period
  [12] AD3TAC4 — ADC Trigger 3 on Timer A compare 4
  [11] AD3TAC3 — ADC Trigger 3 on Timer A compare 3
  [10] AD3TFC2 — ADC Trigger 3 on Timer F compare 2
  [n+4] AD3EEV{n} (n=1..5) — ADC Trigger 3 on external event {n}
  [4] AD3MPER — ADC Trigger 3 on master period
  [n-1] AD3MC{n} (n=1..4) — ADC Trigger 3 on master compare {n}
0x3C8 ADC4R — HRTIM ADC Trigger 4 register
  [31] AD4TERST — ADC Trigger 4 on Timer E reset
  [30] AD4TEC4 — ADC Trigger 4 on Timer E compare 4
  [29] AD4TEC3 — ADC Trigger 4 on Timer E compare 3
  [28] AD4TEC2 — ADC Trigger 4 on Timer E compare 2
  [27] AD4TDRST — ADC Trigger 4 on Timer D reset
  [26] AD4TDPER — ADC Trigger 4 on Timer D period
  [25] AD4TDC4 — ADC Trigger 4 on Timer D compare 4
  [24] AD4TFPER — ADC Trigger 4 on Timer F period
  [23] AD4TDC2 — ADC Trigger 4 on Timer D compare 2
  [22] AD4TCRST — ADC Trigger 4 on Timer C reset
  [21] AD4TCPER — ADC Trigger 4 on Timer C period
  [20] AD4TCC4 — ADC Trigger 4 on Timer C compare 4
  [19] AD4TFC4 — ADC Trigger 4 on Timer F compare 4
  [18] AD4TCC2 — ADC Trigger 4 on Timer C compare 2
  [17] AD4TBPER — ADC Trigger 4 on Timer B period
  [16] AD4TBC4 — ADC Trigger 4 on Timer B compare 4
  [15] AD4TFC3 — ADC Trigger 4 on Timer F compare 3
  [14] AD4TBC2 — ADC Trigger 4 on Timer B compare 2
  [13] AD4TAPER — ADC Trigger 4 on Timer A period
  [12] AD4TAC4 — ADC Trigger 4 on Timer A compare 4
  [11] AD4TFC2 — ADC Trigger 4 on Timer F compare 2
  [10] AD4TAC2 — ADC Trigger 4 on Timer A compare 2
  [n-1] AD4EEV{n} (n=6..10) — ADC Trigger 4 on external event {n}
  [4] AD4MPER — ADC Trigger 4 on master period
  [n-1] AD4MC{n} (n=1..4) — ADC Trigger 4 on master compare {n}
0x3CC DLLCR — HRTIM DLL control register
  [3:2] CALRTE — DLL calibration rate
  [1] CALEN — DLL calibration enable
  [0] CAL — DLL calibration start
0x3D0 FLTINR1 — HRTIM Fault input register1
  [8n-1] FLT{n}LCK (n=1..4) — Fault {n} lock
  [8n-2:8n-5] FLT{n}F (n=1..4) — Fault {n} filter
  [8n-6] FLT{n}SRC_0 (n=1..4) — Fault {n} source bit 0
  [8n-7] FLT{n}P (n=1..4) — Fault {n} polarity
  [8n-8] FLT{n}E (n=1..4) — Fault {n} enable
0x3D4 FLTINR2 — HRTIM Fault input register2
  [25:24] FLTSD — Fault sampling clock division
  [n+15] FLT{n}SRC_1 (n=3..6) — Fault {n} source bit 1
  [17] FLT2SRC_1 — Fault 2 source bit1
  [16] FLT1SRC_1 — Fault 1 source bit 1
  [15] FLT6LCK — Fault 6 lock
  [14:11] FLT6F — Fault 6 filter
  [10] FLT6SRC_0 — Fault 6 source bit 0
  [9] FLT6P — Fault 6 polarity
  [8] FLT6E — Fault 6 enable
  [7] FLT5LCK — Fault 5 lock
  [6:3] FLT5F — Fault 5 filter
  [2] FLT5SRC_0 — Fault 5 source bit 0
  [1] FLT5P — Fault 5 polarity
  [0] FLT5E — Fault 5 enable
0x3D8 BDMUPR — HRTIM Burst DMA Master Timer update register
  [9] MCMP4 — MPCMP4 register update enable
  [8] MCMP3 — MCMP3 register update enable
  [7] MCMP2 — MCMP2 register update enable
  [6] MCMP1 — MCMP1 register update enable
  [5] MREP — MREP register update enable
  [4] MPER — MPER register update enable
  [3] MCNT — MCNT register update enable
  [2] MDIER — MDIER register update enable
  [1] MICR — MICR register update enable
  [0] MCR — MCR register update enable
0x3DC BDTAUPR — HRTIM Burst DMA Timerx update register
0x3E0 BDTBUPR — HRTIM Burst DMA Timerx update register
0x3E4 BDTCUPR — HRTIM Burst DMA Timerx update register
0x3E8 BDTDUPR — HRTIM Burst DMA Timerx update register
0x3EC BDTEUPR — HRTIM Burst DMA Timerx update register
0x3F0 BDMADR — HRTIM Burst DMA Master Data register
  [31:0] BDMADR — Burst DMA Data register
0x3F4 BDTFUPR — HRTIM Burst DMA Timerx update register
0x3F8 ADCER — HRTIM ADC Extended Trigger register
  [30:26] AD10TRG — ADC10 trigger
  [25:21] AD9TRG — ADC9 trigger
  [20:16] AD8TRG — ADC8 trigger
  [14:10] AD7TRG — ADC7 trigger
  [9:5] AD6TRG — ADC6 trigger
  [4:0] AD5TRG — ADC5 trigger
0x3FC ADCUR — HRTIM ADC Trigger Update register
  [4n-18:4n-20] AD{n}USRC (n=5..10) — ADC{n} trigger Update Source
0x400 ADCPS1 — HRTIM ADC Post Scaler Register 1
  [6n-2:6n-6] AD{n}PSC (n=1..5) — ADC{n} post scaler
0x404 ADCPS2 — HRTIM ADC Post Scaler Register 2
  [6n-32:6n-36] AD{n}PSC (n=6..10) — ADC{n} post scaler
0x408 FLTINR3 — HRTIM Fault input register3
  [8n-1] FLT{n}RSTM (n=1..4) — Fault {n} Counter Reset Mode
  [8n-2] FLT{n}CRES (n=1..4) — Fault {n} Counter Reset
  [8n-3:8n-6] FLT{n}CNT (n=1..4) — Fault {n} Counter
  [8n-7] FLT{n}BLKS (n=1..4) — Fault {n} Blanking Source
  [8n-8] FLT{n}BLKE (n=1..4) — Fault {n} Blanking Enable
0x40C FLTINR4 — HRTIM Fault input register4
  [15] FLT6RSTM — Fault 6 Counter Reset Mode
  [14] FLT6CRES — Fault 6 Counter Reset
  [13:10] FLT6CNT — Fault 6 Counter
  [9] FLT6BLKS — Fault 6 Blanking Source
  [8] FLT6BLKE — Fault 6 Blanking Enable
  [7] FLT5RSTM — Fault 5 Counter Reset Mode
  [6] FLT5CRES — Fault 5 Counter Reset
  [5:2] FLT5CNT — Fault 5 Counter
  [1] FLT5BLKS — Fault 5 Blanking Source
  [0] FLT5BLKE — Fault 5 Blanking Enable
